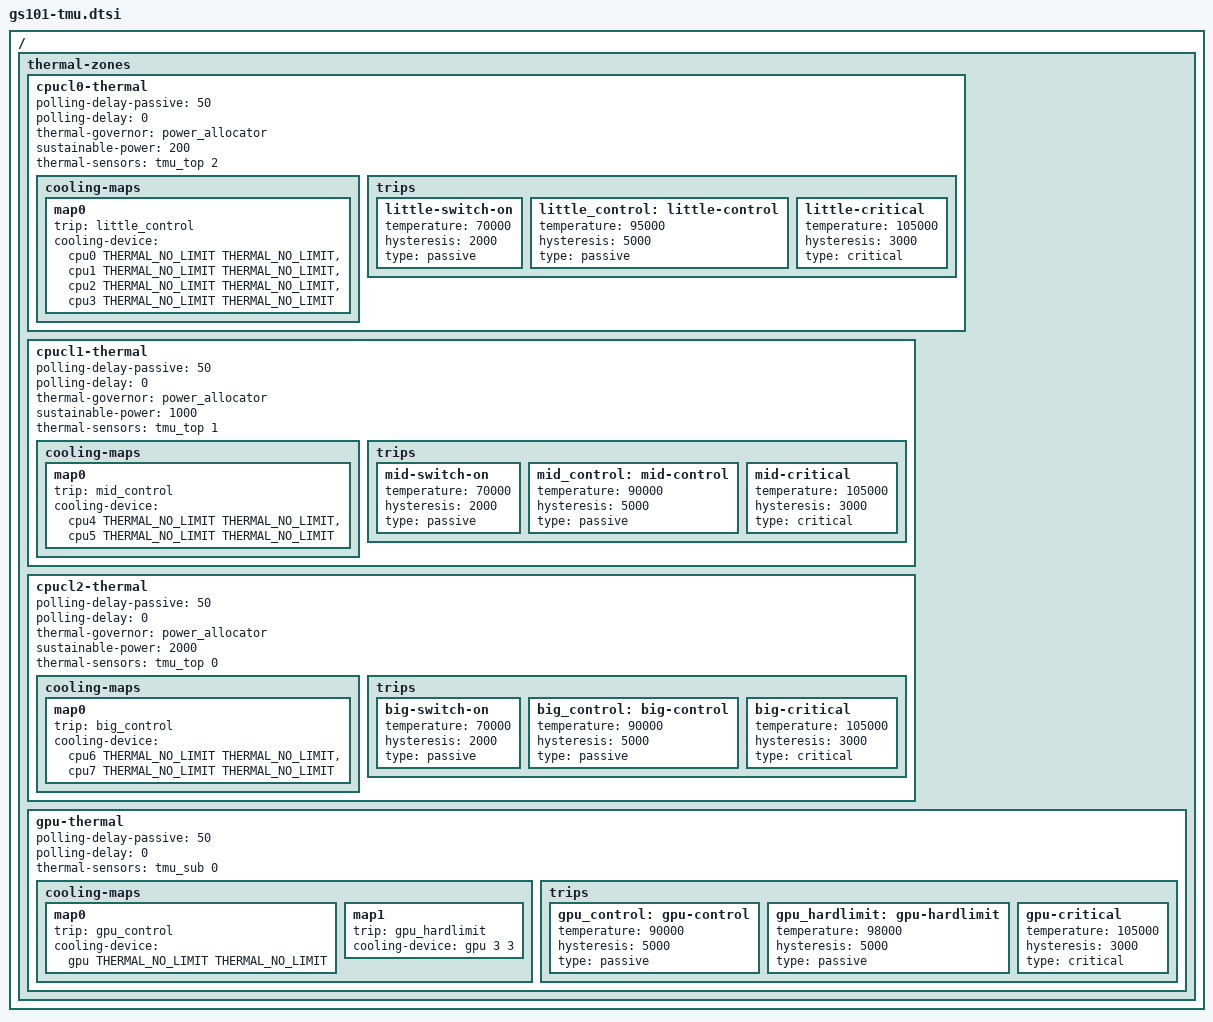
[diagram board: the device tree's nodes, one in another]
// SPDX-License-Identifier: GPL-2.0-only
/*
 * Google GS101 TMU configurations device tree source
 *
 * Copyright 2020 Samsung Electronics Co., Ltd.
 * Copyright 2020 Google LLC.
 * Copyright 2026 Linaro Ltd.
 */

#include <dt-bindings/thermal/thermal.h>

/*
 * The zones follow stock's: from 70 °C the CPU clusters are held at their
 * control temperature by the power allocator, polled every 50 ms, with
 * stock's sustainable power for each. The X1 cores heat by tens of degrees
 * in a tenth of a second at their top clock, so a slower loop lets them
 * overshoot. Stock also limits the clusters in the TMU and ACPM (hardware
 * throttling and hard limits from 98-103 °C, the X1 and A76 cores paused
 * at 108 °C) and powers off only past 115 °C. None of those limits is
 * here yet, so the critical trips stay at 105 °C; they move to stock's
 * 115 °C together with those limits. The GPU has no power model, so its
 * zone steps its clock instead, down to the lowest at stock's hard limit.
 */
/ {
	thermal-zones {
		cpucl0-thermal {
			polling-delay-passive = <50>;
			polling-delay = <0>;
			thermal-governor = "power_allocator";
			sustainable-power = <200>;
			thermal-sensors = <&tmu_top 2>;

			cooling-maps {
				map0 {
					trip = <&little_control>;
					cooling-device = <&cpu0 THERMAL_NO_LIMIT THERMAL_NO_LIMIT>,
							 <&cpu1 THERMAL_NO_LIMIT THERMAL_NO_LIMIT>,
							 <&cpu2 THERMAL_NO_LIMIT THERMAL_NO_LIMIT>,
							 <&cpu3 THERMAL_NO_LIMIT THERMAL_NO_LIMIT>;
				};
			};

			trips {
				little-switch-on {
					temperature = <70000>;
					hysteresis = <2000>;
					type = "passive";
				};

				little_control: little-control {
					temperature = <95000>;
					hysteresis = <5000>;
					type = "passive";
				};

				little-critical {
					temperature = <105000>;
					hysteresis = <3000>;
					type = "critical";
				};
			};
		};

		cpucl1-thermal {
			polling-delay-passive = <50>;
			polling-delay = <0>;
			thermal-governor = "power_allocator";
			sustainable-power = <1000>;
			thermal-sensors = <&tmu_top 1>;

			cooling-maps {
				map0 {
					trip = <&mid_control>;
					cooling-device = <&cpu4 THERMAL_NO_LIMIT THERMAL_NO_LIMIT>,
							 <&cpu5 THERMAL_NO_LIMIT THERMAL_NO_LIMIT>;
				};
			};

			trips {
				mid-switch-on {
					temperature = <70000>;
					hysteresis = <2000>;
					type = "passive";
				};

				mid_control: mid-control {
					temperature = <90000>;
					hysteresis = <5000>;
					type = "passive";
				};

				mid-critical {
					temperature = <105000>;
					hysteresis = <3000>;
					type = "critical";
				};
			};
		};

		cpucl2-thermal {
			polling-delay-passive = <50>;
			polling-delay = <0>;
			thermal-governor = "power_allocator";
			sustainable-power = <2000>;
			thermal-sensors = <&tmu_top 0>;

			cooling-maps {
				map0 {
					trip = <&big_control>;
					cooling-device = <&cpu6 THERMAL_NO_LIMIT THERMAL_NO_LIMIT>,
							 <&cpu7 THERMAL_NO_LIMIT THERMAL_NO_LIMIT>;
				};
			};

			trips {
				big-switch-on {
					temperature = <70000>;
					hysteresis = <2000>;
					type = "passive";
				};

				big_control: big-control {
					temperature = <90000>;
					hysteresis = <5000>;
					type = "passive";
				};

				big-critical {
					temperature = <105000>;
					hysteresis = <3000>;
					type = "critical";
				};
			};
		};

		gpu-thermal {
			polling-delay-passive = <50>;
			polling-delay = <0>;
			thermal-sensors = <&tmu_sub 0>;

			cooling-maps {
				map0 {
					trip = <&gpu_control>;
					cooling-device = <&gpu THERMAL_NO_LIMIT THERMAL_NO_LIMIT>;
				};

				map1 {
					trip = <&gpu_hardlimit>;
					cooling-device = <&gpu 3 3>;
				};
			};

			trips {
				gpu_control: gpu-control {
					temperature = <90000>;
					hysteresis = <5000>;
					type = "passive";
				};

				gpu_hardlimit: gpu-hardlimit {
					temperature = <98000>;
					hysteresis = <5000>;
					type = "passive";
				};

				gpu-critical {
					temperature = <105000>;
					hysteresis = <3000>;
					type = "critical";
				};
			};
		};
	};
};
